# f28003x_xbar_regs register map
Vendor: Texas Instruments
Peripheral module from a debugger description file (folder C2000).
Address unit: 16 bits
Registers are 32-bit, read-only, no defined reset value unless marked. A register's access mark holds for its fields unless they carry their own. Offsets are as the file gives them; lines under a group give offsets from that group; [hi:lo] are bit positions; {n}, {i} and the like mark numbered series; 'fields as' and 'values as' point back to an identical list; <NAME> marks a mode.

## XBAR_REGS — XBAR Registers
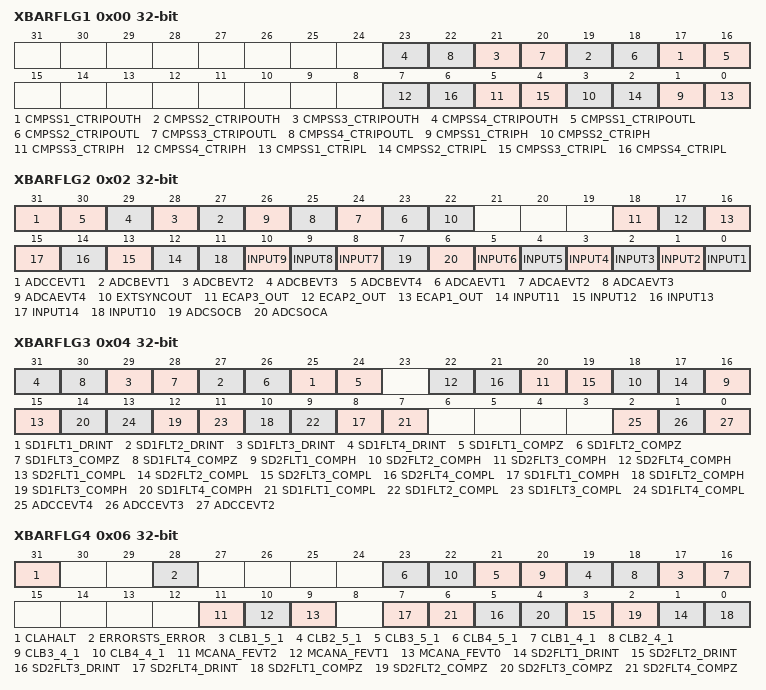
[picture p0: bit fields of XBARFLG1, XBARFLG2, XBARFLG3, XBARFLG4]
0x00 XBARFLG1 — X-Bar Input Flag Register 1
  [2n+15] CMPSS{n}_CTRIPOUTH (n=1..4) — Input Flag for CMPSS{n}.CTRIPOUTH Signal
  [2n+14] CMPSS{n}_CTRIPOUTL (n=1..4) — Input Flag for CMPSS{n}.CTRIPOUTL Signal
  [2n-1] CMPSS{n}_CTRIPH (n=1..4) — Input Flag for CMPSS{n}.CTRIPH Signal
  [2n-2] CMPSS{n}_CTRIPL (n=1..4) — Input Flag for CMPSS{n}.CTRIPL Signal
0x02 XBARFLG2 — X-Bar Input Flag Register 2
  [31] ADCCEVT1 — Input Flag for ADCCEVT1 Signal
  [n+26] ADCBEVT{n} (n=1..4) — Input Flag for ADCBEVT{n} Signal
  [n+22] ADCAEVT{n} (n=1..4) — Input Flag for ADCAEVT{n} Signal
  [22] EXTSYNCOUT — Input Flag for EXTSYNCOUT Signal
  [18] ECAP3_OUT — Input Flag for ECAP3.OUT Signal
  [17] ECAP2_OUT — Input Flag for ECAP2.OUT Signal
  [16] ECAP1_OUT — Input Flag for ECAP1.OUT Signal
  [n+1] INPUT{n} (n=11..14) — Input Flag for INPUT{n} Signal
  [11] INPUT10 — Input Flag for INPUT10\ Signal
  [10] INPUT9 — Input Flag for INPUT9 Signal
  [9] INPUT8 — Input Flag for INPUT8 Signal
  [8] INPUT7 — Input Flag for INPUT7 Signal
  [7] ADCSOCB — Input Flag for ADCSOCB Signal
  [6] ADCSOCA — Input Flag for ADCSOCA Signal
  [n-1] INPUT{n} (n=1..6) — Input Flag for INPUT{n} Signal
0x04 XBARFLG3 — X-Bar Input Flag Register 3
  [2n+23] SD1FLT{n}_DRINT (n=1..4) — Input Flag for SD1FLT{n}.DRINT Signal
  [2n+22] SD1FLT{n}_COMPZ (n=1..4) — Input Flag for SD1FLT{n}.COMPZ Signal
  [2n+14] SD2FLT{n}_COMPH (n=1..4) — Input Flag for SD2FLT{n}.COMPH Signal
  [2n+13] SD2FLT{n}_COMPL (n=1..4) — Input Flag for SD2FLT{n}.COMPL Signal
  [2n+6] SD1FLT{n}_COMPH (n=1..4) — Input Flag for SD1FLT{n}.COMPH Signal
  [2n+5] SD1FLT{n}_COMPL (n=1..4) — Input Flag for SD1FLT{n}.COMPL Signal
  [2] ADCCEVT4 — Input Flag for ADCCEVT4 Signal
  [1] ADCCEVT3 — Input Flag for ADCCEVT3 Signal
  [0] ADCCEVT2 — Input Flag for ADCCEVT2 Signal
0x06 XBARFLG4 — X-Bar Input Flag Register 4
  [31] CLAHALT — Input Flag for CLAHALT Signal
  [28] ERRORSTS_ERROR — Input Latch for ERRORSTS_ERROR Signal
  [2n+15] CLB{n}_5_1 (n=1..4) — Input Flag for CLB{n}_5.1 Signal
  [2n+14] CLB{n}_4_1 (n=1..4) — Input Flag for CLB{n}_4.1 Signal
  [11] MCANA_FEVT2 — Input Flag for MCANA_FEVT2 Signal
  [10] MCANA_FEVT1 — Input Flag for MCANA_FEVT1 Signal
  [9] MCANA_FEVT0 — Input Flag for MCANA_FEVT0 Signal
  [2n-1] SD2FLT{n}_DRINT (n=1..4) — Input Flag for SD2FLT{n}.DRINT Signal
  [2n-2] SD2FLT{n}_COMPZ (n=1..4) — Input Flag for SD2FLT{n}.COMPZ Signal
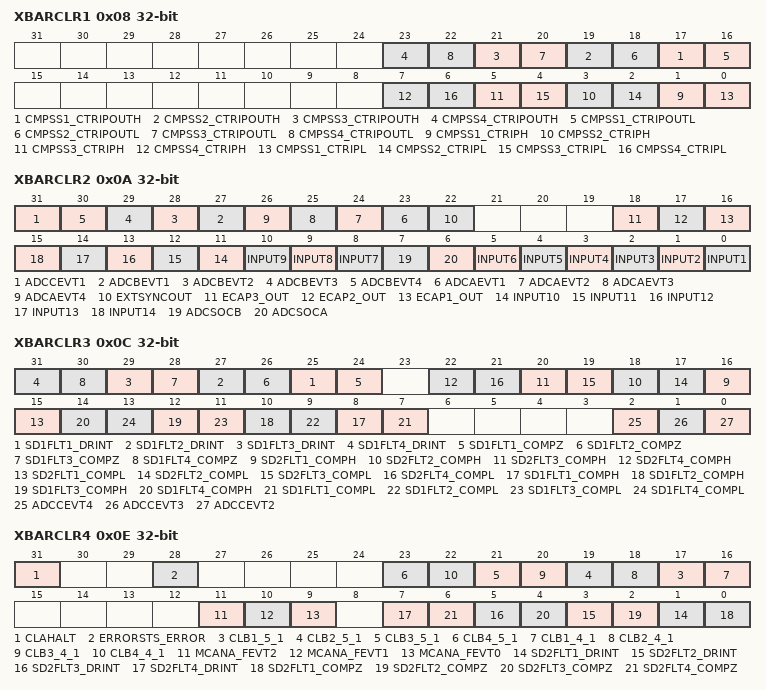
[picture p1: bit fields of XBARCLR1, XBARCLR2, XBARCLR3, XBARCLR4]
0x08 XBARCLR1 rw — X-Bar Input Flag Clear Register 1
  [2n+15] CMPSS{n}_CTRIPOUTH (n=1..4) — Input Flag Clear for CMPSS{n}.CTRIPOUTH Signal
  [2n+14] CMPSS{n}_CTRIPOUTL (n=1..4) — Input Flag Clear for CMPSS{n}.CTRIPOUTL Signal
  [2n-1] CMPSS{n}_CTRIPH (n=1..4) — Input Flag Clear for CMPSS{n}.CTRIPH Signal
  [2n-2] CMPSS{n}_CTRIPL (n=1..4) — Input Flag Clear for CMPSS{n}.CTRIPL Signal
0x0A XBARCLR2 rw — X-Bar Input Flag Clear Register 2
  [31] ADCCEVT1 — Input Flag Clear for ADCCEVT1 Signal
  [n+26] ADCBEVT{n} (n=1..4) — Input Flag Clear for ADCBEVT{n} Signal
  [n+22] ADCAEVT{n} (n=1..4) — Input Flag Clear for ADCAEVT{n} Signal
  [22] EXTSYNCOUT — Input Flag Clear for EXTSYNCOUT Signal
  [18] ECAP3_OUT — Input Flag Clear for ECAP3.OUT Signal
  [17] ECAP2_OUT — Input Flag Clear for ECAP2.OUT Signal
  [16] ECAP1_OUT — Input Flag Clear for ECAP1.OUT Signal
  [n+1] INPUT{n} (n=7..14) — Input Flag Clear for INPUT{n} Signal
  [7] ADCSOCB — Input Flag Clear for ADCSOCB Signal
  [6] ADCSOCA — Input Flag Clear for ADCSOCA Signal
  [n-1] INPUT{n} (n=1..6) — Input Flag Clear for INPUT{n} Signal
0x0C XBARCLR3 rw — X-Bar Input Flag Clear Register 3
  [2n+23] SD1FLT{n}_DRINT (n=1..4) — Input Flag clear for SD1FLT{n}.DRINT Signal
  [2n+22] SD1FLT{n}_COMPZ (n=1..4) — Input Flag clear for SD1FLT{n}.COMPZ Signal
  [2n+14] SD2FLT{n}_COMPH (n=1..4) — Input Flag Clear for SD2FLT{n}.COMPH Signal
  [2n+13] SD2FLT{n}_COMPL (n=1..4) — Input Flag Clear for SD2FLT{n}.COMPL Signal
  [2n+6] SD1FLT{n}_COMPH (n=1..4) — Input Flag Clear for SD1FLT{n}.COMPH Signal
  [2n+5] SD1FLT{n}_COMPL (n=1..4) — Input Flag Clear for SD1FLT{n}.COMPL Signal
  [2] ADCCEVT4 — Input Flag Clear for ADCCEVT4 Signal
  [1] ADCCEVT3 — Input Flag Clear for ADCCEVT3 Signal
  [0] ADCCEVT2 — Input Flag Clear for ADCCEVT2 Signal
0x0E XBARCLR4 access per field — X-Bar Input Flag Clear Register 4
  [31] CLAHALT ro — Input Flag clear for CLAHALT Signal
  [28] ERRORSTS_ERROR rw — Input Latch clear for ERRORSTS_ERROR Signal
  [2n+15] CLB{n}_5_1 ro (n=1..4) — Input Flag clear for CLB{n}_5.1 Signal
  [2n+14] CLB{n}_4_1 ro (n=1..4) — Input Flag clear for CLB{n}_4.1 Signal
  [11] MCANA_FEVT2 rw — Input Flag clear for MCANA_FEVT2 Signal
  [10] MCANA_FEVT1 rw — Input Flag clear for MCANA_FEVT1 Signal
  [9] MCANA_FEVT0 rw — Input Flag clear for MCANA_FEVT0 Signal
  [2n-1] SD2FLT{n}_DRINT ro (n=1..4) — Input Flag clear for SD2FLT{n}.DRINT Signal
  [2n-2] SD2FLT{n}_COMPZ ro (n=1..4) — Input Flag clear for SD2FLT{n}.COMPZ Signal
